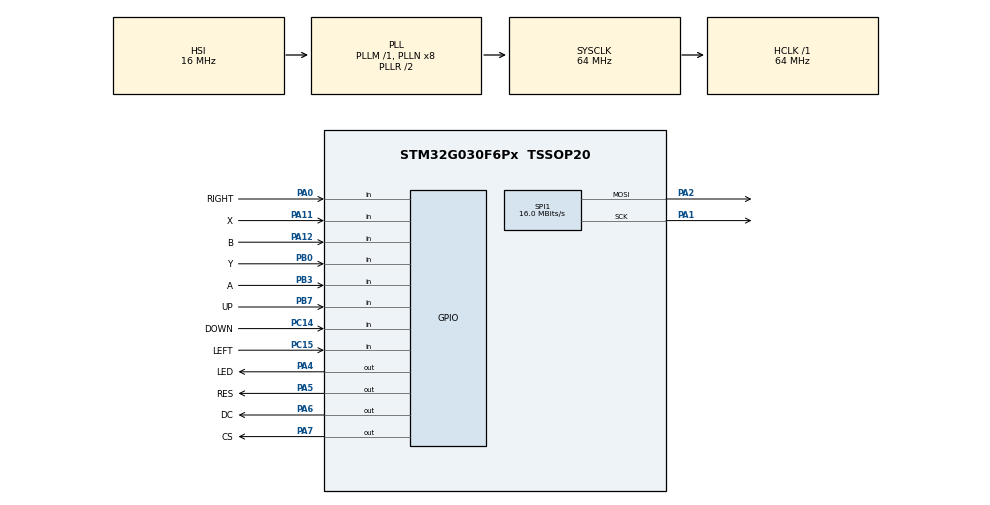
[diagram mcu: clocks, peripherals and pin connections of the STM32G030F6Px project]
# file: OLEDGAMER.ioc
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Mcu.Family=STM32G0
Mcu.Name=STM32G030F6Px
Mcu.Package=TSSOP20
PA0.GPIO_Label=RIGHT
PA0.GPIO_PuPd=GPIO_PULLUP
PA0.Signal=GPIO_Input
PA1.Mode=TX_Only_Simplex_Unidirect_Master
PA1.Signal=SPI1_SCK
PA11\ [PA9].GPIO_Label=X
PA11\ [PA9].GPIO_PuPd=GPIO_PULLUP
PA11\ [PA9].Signal=GPIO_Input
PA12\ [PA10].GPIO_Label=B
PA12\ [PA10].GPIO_PuPd=GPIO_PULLUP
PA12\ [PA10].Signal=GPIO_Input
PA13.Mode=Serial_Wire
PA13.Signal=SYS_SWDIO
PA14-BOOT0.Mode=Serial_Wire
PA14-BOOT0.Signal=SYS_SWCLK
PA2.Mode=TX_Only_Simplex_Unidirect_Master
PA2.Signal=SPI1_MOSI
PA4.GPIO_Label=LED
PA4.Signal=GPIO_Output
PA5.GPIO_Label=RES
PA5.GPIO_Speed=GPIO_SPEED_FREQ_VERY_HIGH
PA5.Signal=GPIO_Output
PA6.GPIO_Label=DC
PA6.GPIO_Speed=GPIO_SPEED_FREQ_VERY_HIGH
PA6.Signal=GPIO_Output
PA7.GPIO_Label=CS
PA7.GPIO_Speed=GPIO_SPEED_FREQ_VERY_HIGH
PA7.Signal=GPIO_Output
PB0.GPIO_Label=Y
PB0.GPIO_PuPd=GPIO_PULLUP
PB0.Signal=GPIO_Input
PB3.GPIO_Label=A
PB3.GPIO_PuPd=GPIO_PULLUP
PB3.Signal=GPIO_Input
PB7.GPIO_Label=UP
PB7.GPIO_PuPd=GPIO_PULLUP
PB7.Signal=GPIO_Input
PC14-OSC32_IN\ (PC14).GPIO_Label=DOWN
PC14-OSC32_IN\ (PC14).GPIO_PuPd=GPIO_PULLUP
PC14-OSC32_IN\ (PC14).Signal=GPIO_Input
PC15-OSC32_OUT\ (PC15).GPIO_Label=LEFT
PC15-OSC32_OUT\ (PC15).GPIO_PuPd=GPIO_PULLUP
PC15-OSC32_OUT\ (PC15).Signal=GPIO_Input
ProjectManager.HeapSize=0x200
ProjectManager.StackSize=0x400
ProjectManager.TargetToolchain=Makefile
RCC.ADCFreq_Value=64000000
RCC.AHBFreq_Value=64000000
RCC.APB1CLKDivider=RCC_HCLK_DIV2
RCC.CortexFreq_Value=64000000
RCC.EXTERNAL_CLOCK_VALUE=12288000
RCC.HCLKFreq_Value=64000000
RCC.HSE_VALUE=8000000
RCC.HSI_VALUE=16000000
RCC.LSE_VALUE=32768
RCC.SYSCLKFreq_VALUE=64000000
RCC.SYSCLKSource=RCC_SYSCLKSOURCE_PLLCLK
RCC.VCOOutputFreq_Value=128000000
SPI1.CLKPhase=SPI_PHASE_2EDGE
SPI1.CLKPolarity=SPI_POLARITY_HIGH
SPI1.CalculateBaudRate=16.0 MBits/s
SPI1.Direction=SPI_DIRECTION_2LINES
SPI1.Mode=SPI_MODE_MASTER
SPI1.VirtualType=VM_MASTER
board=custom

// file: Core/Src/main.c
/* USER CODE BEGIN Header */
/**
  ******************************************************************************
  * @file           : main.c
  * @brief          : Main program body
  ******************************************************************************
  * @attention
  *
  * <h2><center>&copy; Copyright (c) 2021 STMicroelectronics.
  * All rights reserved.</center></h2>
  *
  * This software component is licensed by ST under BSD 3-Clause license,
  * the "License"; You may not use this file except in compliance with the
  * License. You may obtain a copy of the License at:
  *                        opensource.org/licenses/BSD-3-Clause
  *
  ******************************************************************************
  */
/* USER CODE END Header */
#include "main.h"
#include "spi.h"
#include "gpio.h"

/* USER CODE BEGIN Includes */
#include "S_SYSTICK.h"
#include "S_U8G2.h"
/* USER CODE END Includes */

void SystemClock_Config(void);
/* USER CODE BEGIN PFP */
void ledtoggle(void);
/* USER CODE END PFP */

int main(void)
{

  /* MCU Configuration--------------------------------------------------------*/

  /* Reset of all peripherals, Initializes the Flash interface and the Systick. */
  HAL_Init();

  /* Configure the system clock */
  SystemClock_Config();

  /* Initialize all configured peripherals */
  MX_GPIO_Init();
  MX_SPI1_Init();
  /* USER CODE BEGIN 2 */

  //定时操作结构体
  Period_t led0 = {1000, &ledtoggle, -1, 0};
  Period_t mainpage = {20, &u8g2mainpage, -1, 0};
  Period_t KEYSCAN = {2, &keyscan, -1, 0};
  //初始化屏幕
  u8g2init();
  /* USER CODE END 2 */

  /* Infinite loop */
  while (1)
  {

    /* USER CODE BEGIN 3 */

    //三个定时任务
    do_sth_period(&led0);//1s周期闪烁运行指示灯
    do_sth_period(&KEYSCAN);//2ms一次的按键扫描
    do_sth_period(&mainpage);//20ms一次游戏机主体操作,理论帧数在50fps?
  }
  /* USER CODE END 3 */
}

void SystemClock_Config(void)
{
  RCC_OscInitTypeDef RCC_OscInitStruct = {0};
  RCC_ClkInitTypeDef RCC_ClkInitStruct = {0};

  /** Configure the main internal regulator output voltage
  */
  HAL_PWREx_ControlVoltageScaling(PWR_REGULATOR_VOLTAGE_SCALE1);
  /** Initializes the RCC Oscillators according to the specified parameters
  * in the RCC_OscInitTypeDef structure.
  */
  RCC_OscInitStruct.OscillatorType = RCC_OSCILLATORTYPE_HSI;
  RCC_OscInitStruct.HSIState = RCC_HSI_ON;
  RCC_OscInitStruct.HSIDiv = RCC_HSI_DIV1;
  RCC_OscInitStruct.HSICalibrationValue = RCC_HSICALIBRATION_DEFAULT;
  RCC_OscInitStruct.PLL.PLLState = RCC_PLL_ON;
  RCC_OscInitStruct.PLL.PLLSource = RCC_PLLSOURCE_HSI;
  RCC_OscInitStruct.PLL.PLLM = RCC_PLLM_DIV1;
  RCC_OscInitStruct.PLL.PLLN = 8;
  RCC_OscInitStruct.PLL.PLLP = RCC_PLLP_DIV2;
  RCC_OscInitStruct.PLL.PLLR = RCC_PLLR_DIV2;
  if (HAL_RCC_OscConfig(&RCC_OscInitStruct) != HAL_OK)
  {
    Error_Handler();
  }
  /** Initializes the CPU, AHB and APB buses clocks
  */
  RCC_ClkInitStruct.ClockType = RCC_CLOCKTYPE_HCLK|RCC_CLOCKTYPE_SYSCLK
                              |RCC_CLOCKTYPE_PCLK1;
  RCC_ClkInitStruct.SYSCLKSource = RCC_SYSCLKSOURCE_PLLCLK;
  RCC_ClkInitStruct.AHBCLKDivider = RCC_SYSCLK_DIV1;
  RCC_ClkInitStruct.APB1CLKDivider = RCC_HCLK_DIV2;

  if (HAL_RCC_ClockConfig(&RCC_ClkInitStruct, FLASH_LATENCY_2) != HAL_OK)
  {
    Error_Handler();
  }
}

/* USER CODE BEGIN 4 */
void ledtoggle(void)
{
  HAL_GPIO_TogglePin(LED_GPIO_Port, LED_Pin);
}
/* USER CODE END 4 */

void Error_Handler(void)
{
  __disable_irq();
  while (1)
  {
  }
}

/************************ (C) COPYRIGHT STMicroelectronics *****END OF FILE****/
